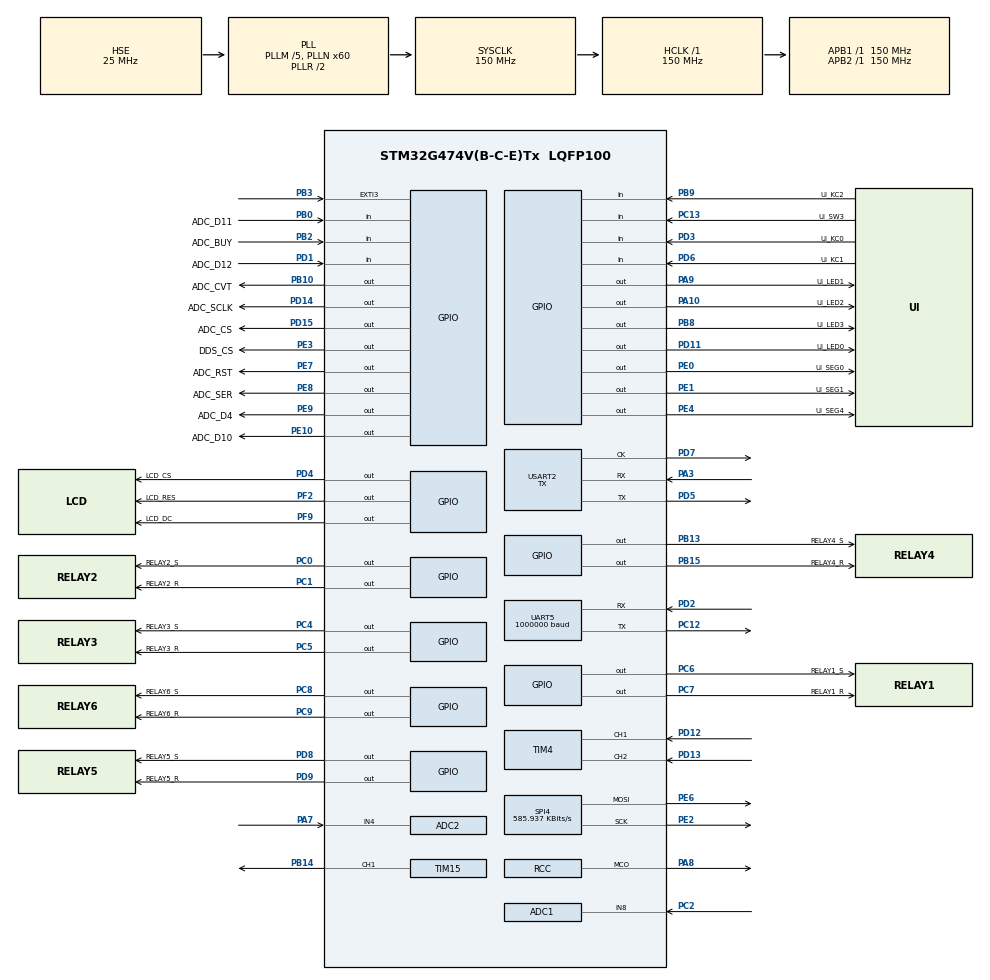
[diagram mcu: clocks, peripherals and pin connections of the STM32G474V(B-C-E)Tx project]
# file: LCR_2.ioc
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ADC1.Channel-3\#ChannelRegularConversion=ADC_CHANNEL_8
ADC1.ClockPrescaler=ADC_CLOCK_ASYNC_DIV1
ADC1.ExternalTrigConv=ADC_EXTERNALTRIG_T6_TRGO
ADC1.NbrOfConversionFlag=1
ADC1.OffsetNumber-3\#ChannelRegularConversion=ADC_OFFSET_NONE
ADC1.Rank-3\#ChannelRegularConversion=1
ADC1.SamplingTime-3\#ChannelRegularConversion=ADC_SAMPLETIME_2CYCLES_5
ADC1.master=1
ADC2.Channel-4\#ChannelRegularConversion=ADC_CHANNEL_4
ADC2.ClockPrescaler=ADC_CLOCK_ASYNC_DIV1
ADC2.ExternalTrigConv=ADC_EXTERNALTRIG_T6_TRGO
ADC2.NbrOfConversionFlag=1
ADC2.OffsetNumber-4\#ChannelRegularConversion=ADC_OFFSET_NONE
ADC2.Rank-4\#ChannelRegularConversion=1
ADC2.SamplingTime-4\#ChannelRegularConversion=ADC_SAMPLETIME_2CYCLES_5
CRC.CRCLength=CRC_POLYLENGTH_16B
CRC.DefaultInitValueUse=DEFAULT_INIT_VALUE_DISABLE
CRC.DefaultPolynomialUse=DEFAULT_POLYNOMIAL_DISABLE
CRC.GeneratingPolynomial=X12+X5+X0
CRC.InputDataInversionMode=CRC_INPUTDATA_INVERSION_NONE
Dma.ADC1.2.Direction=DMA_PERIPH_TO_MEMORY
Dma.ADC1.2.EventEnable=DISABLE
Dma.ADC1.2.Instance=DMA1_Channel1
Dma.ADC1.2.MemDataAlignment=DMA_MDATAALIGN_HALFWORD
Dma.ADC1.2.MemInc=DMA_MINC_ENABLE
Dma.ADC1.2.Mode=DMA_NORMAL
Dma.ADC1.2.PeriphDataAlignment=DMA_PDATAALIGN_HALFWORD
Dma.ADC1.2.PeriphInc=DMA_PINC_DISABLE
Dma.ADC1.2.Polarity=HAL_DMAMUX_REQ_GEN_RISING
Dma.ADC1.2.Priority=DMA_PRIORITY_LOW
Dma.ADC1.2.RequestNumber=1
Dma.ADC1.2.SignalID=NONE
Dma.ADC1.2.SyncEnable=DISABLE
Dma.ADC1.2.SyncPolarity=HAL_DMAMUX_SYNC_NO_EVENT
Dma.ADC1.2.SyncRequestNumber=1
Dma.ADC1.2.SyncSignalID=NONE
Dma.ADC2.3.Direction=DMA_PERIPH_TO_MEMORY
Dma.ADC2.3.EventEnable=DISABLE
Dma.ADC2.3.Instance=DMA1_Channel2
Dma.ADC2.3.MemDataAlignment=DMA_MDATAALIGN_HALFWORD
Dma.ADC2.3.MemInc=DMA_MINC_ENABLE
Dma.ADC2.3.Mode=DMA_NORMAL
Dma.ADC2.3.PeriphDataAlignment=DMA_PDATAALIGN_HALFWORD
Dma.ADC2.3.PeriphInc=DMA_PINC_DISABLE
Dma.ADC2.3.Polarity=HAL_DMAMUX_REQ_GEN_RISING
Dma.ADC2.3.Priority=DMA_PRIORITY_LOW
Dma.ADC2.3.RequestNumber=1
Dma.ADC2.3.SignalID=NONE
Dma.ADC2.3.SyncEnable=DISABLE
Dma.ADC2.3.SyncPolarity=HAL_DMAMUX_SYNC_NO_EVENT
Dma.ADC2.3.SyncRequestNumber=1
Dma.ADC2.3.SyncSignalID=NONE
Dma.CORDIC_READ.0.Direction=DMA_PERIPH_TO_MEMORY
Dma.CORDIC_READ.0.EventEnable=DISABLE
Dma.CORDIC_READ.0.Instance=DMA1_Channel3
Dma.CORDIC_READ.0.MemDataAlignment=DMA_MDATAALIGN_WORD
Dma.CORDIC_READ.0.MemInc=DMA_MINC_ENABLE
Dma.CORDIC_READ.0.Mode=DMA_NORMAL
Dma.CORDIC_READ.0.PeriphDataAlignment=DMA_PDATAALIGN_WORD
Dma.CORDIC_READ.0.PeriphInc=DMA_PINC_DISABLE
Dma.CORDIC_READ.0.Polarity=HAL_DMAMUX_REQ_GEN_RISING
Dma.CORDIC_READ.0.Priority=DMA_PRIORITY_LOW
Dma.CORDIC_READ.0.RequestNumber=1
Dma.CORDIC_READ.0.SignalID=NONE
Dma.CORDIC_READ.0.SyncEnable=DISABLE
Dma.CORDIC_READ.0.SyncPolarity=HAL_DMAMUX_SYNC_NO_EVENT
Dma.CORDIC_READ.0.SyncRequestNumber=1
Dma.CORDIC_READ.0.SyncSignalID=NONE
Dma.CORDIC_WRITE.1.Direction=DMA_MEMORY_TO_PERIPH
Dma.CORDIC_WRITE.1.EventEnable=DISABLE
Dma.CORDIC_WRITE.1.Instance=DMA1_Channel4
Dma.CORDIC_WRITE.1.MemDataAlignment=DMA_MDATAALIGN_WORD
Dma.CORDIC_WRITE.1.MemInc=DMA_MINC_ENABLE
Dma.CORDIC_WRITE.1.Mode=DMA_NORMAL
Dma.CORDIC_WRITE.1.PeriphDataAlignment=DMA_PDATAALIGN_WORD
Dma.CORDIC_WRITE.1.PeriphInc=DMA_PINC_DISABLE
Dma.CORDIC_WRITE.1.Polarity=HAL_DMAMUX_REQ_GEN_RISING
Dma.CORDIC_WRITE.1.Priority=DMA_PRIORITY_LOW
Dma.CORDIC_WRITE.1.RequestNumber=1
Dma.CORDIC_WRITE.1.SignalID=NONE
Dma.CORDIC_WRITE.1.SyncEnable=DISABLE
Dma.CORDIC_WRITE.1.SyncPolarity=HAL_DMAMUX_SYNC_NO_EVENT
Dma.CORDIC_WRITE.1.SyncRequestNumber=1
Dma.CORDIC_WRITE.1.SyncSignalID=NONE
Dma.Request0=CORDIC_READ
Dma.Request1=CORDIC_WRITE
Dma.Request2=ADC1
Dma.Request3=ADC2
Dma.Request4=UART5_RX
Dma.UART5_RX.4.Direction=DMA_PERIPH_TO_MEMORY
Dma.UART5_RX.4.EventEnable=DISABLE
Dma.UART5_RX.4.Instance=DMA1_Channel5
Dma.UART5_RX.4.MemDataAlignment=DMA_MDATAALIGN_BYTE
Dma.UART5_RX.4.MemInc=DMA_MINC_ENABLE
Dma.UART5_RX.4.Mode=DMA_CIRCULAR
Dma.UART5_RX.4.PeriphDataAlignment=DMA_PDATAALIGN_BYTE
Dma.UART5_RX.4.PeriphInc=DMA_PINC_DISABLE
Dma.UART5_RX.4.Polarity=HAL_DMAMUX_REQ_GEN_RISING
Dma.UART5_RX.4.Priority=DMA_PRIORITY_LOW
Dma.UART5_RX.4.RequestNumber=1
Dma.UART5_RX.4.SignalID=NONE
Dma.UART5_RX.4.SyncEnable=DISABLE
Dma.UART5_RX.4.SyncPolarity=HAL_DMAMUX_SYNC_NO_EVENT
Dma.UART5_RX.4.SyncRequestNumber=1
Dma.UART5_RX.4.SyncSignalID=NONE
Mcu.Family=STM32G4
Mcu.Name=STM32G474V(B-C-E)Tx
Mcu.Package=LQFP100
NVIC.DMA1_Channel1_IRQn=true\:0\:0\:false\:false\:true\:false\:true\:true
NVIC.DMA1_Channel2_IRQn=true\:0\:0\:false\:false\:true\:false\:true\:true
NVIC.DMA1_Channel3_IRQn=true\:0\:0\:false\:false\:true\:false\:true\:true
NVIC.DMA1_Channel4_IRQn=true\:0\:0\:false\:false\:true\:false\:true\:true
NVIC.DMA1_Channel5_IRQn=true\:0\:0\:false\:false\:true\:false\:true\:true
NVIC.PriorityGroup=NVIC_PRIORITYGROUP_4
NVIC.UART5_IRQn=true\:0\:0\:false\:false\:true\:true\:true\:true
PA10.GPIO_Label=UI_LED2
PA10.Signal=GPIO_Output
PA3.Mode=Synchronous
PA3.Signal=USART2_RX
PA7.Mode=IN4-Single-Ended
PA7.Signal=ADC2_IN4
PA8.GPIO_Speed=GPIO_SPEED_FREQ_VERY_HIGH
PA8.Mode=Clock-out
PA8.Signal=RCC_MCO
PA9.GPIO_Label=UI_LED1
PA9.Signal=GPIO_Output
PB0.GPIO_Label=ADC_D11
PB0.Signal=GPIO_Input
PB10.GPIO_Label=ADC_CVT
PB10.Signal=GPIO_Output
PB13.GPIO_Label=RELAY4_S
PB13.Signal=GPIO_Output
PB14.Signal=S_TIM15_CH1
PB15.GPIO_Label=RELAY4_R
PB15.Signal=GPIO_Output
PB2.GPIO_Label=ADC_BUY
PB2.Signal=GPIO_Input
PB3.Signal=GPXTI3
PB8-BOOT0.GPIO_Label=UI_LED3
PB8-BOOT0.Signal=GPIO_Output
PB9.GPIO_Label=UI_KC2
PB9.GPIO_PuPd=GPIO_PULLDOWN
PB9.Signal=GPIO_Input
PC0.GPIO_Label=RELAY2_S
PC0.Signal=GPIO_Output
PC1.GPIO_Label=RELAY2_R
PC1.Signal=GPIO_Output
PC12.Mode=Asynchronous
PC12.Signal=UART5_TX
PC13.GPIO_Label=UI_SW3
PC13.GPIO_PuPd=GPIO_PULLUP
PC13.Signal=GPIO_Input
PC2.Mode=IN8-Single-Ended
PC2.Signal=ADC1_IN8
PC4.GPIO_Label=RELAY3_S
PC4.Signal=GPIO_Output
PC5.GPIO_Label=RELAY3_R
PC5.Signal=GPIO_Output
PC6.GPIO_Label=RELAY1_S
PC6.Signal=GPIO_Output
PC7.GPIO_Label=RELAY1_R
PC7.Signal=GPIO_Output
PC8.GPIO_Label=RELAY6_S
PC8.Signal=GPIO_Output
PC9.GPIO_Label=RELAY6_R
PC9.Signal=GPIO_Output
PD1.GPIO_Label=ADC_D12
PD1.Signal=GPIO_Input
PD11.GPIO_Label=UI_LED0
PD11.Signal=GPIO_Output
PD12.Signal=S_TIM4_CH1
PD13.Signal=S_TIM4_CH2
PD14.GPIO_Label=ADC_SCLK
PD14.Signal=GPIO_Output
PD15.GPIO_Label=ADC_CS
PD15.Signal=GPIO_Output
PD2.Mode=Asynchronous
PD2.Signal=UART5_RX
PD3.GPIO_Label=UI_KC0
PD3.GPIO_PuPd=GPIO_PULLDOWN
PD3.Signal=GPIO_Input
PD4.GPIO_Label=LCD_CS
PD4.Signal=GPIO_Output
PD5.Mode=Synchronous
PD5.Signal=USART2_TX
PD6.GPIO_Label=UI_KC1
PD6.GPIO_PuPd=GPIO_PULLDOWN
PD6.Signal=GPIO_Input
PD7.Mode=Synchronous
PD7.Signal=USART2_CK
PD8.GPIO_Label=RELAY5_S
PD8.Signal=GPIO_Output
PD9.GPIO_Label=RELAY5_R
PD9.Signal=GPIO_Output
PE0.GPIO_Label=UI_SEG0
PE0.Signal=GPIO_Output
PE1.GPIO_Label=UI_SEG1
PE1.Signal=GPIO_Output
PE10.GPIO_Label=ADC_D10
PE10.GPIO_PuPd=GPIO_PULLUP
PE10.GPIO_Speed=GPIO_SPEED_FREQ_VERY_HIGH
PE10.PinState=GPIO_PIN_RESET
PE10.Signal=GPIO_Output
PE2.GPIO_PuPd=GPIO_PULLUP
PE2.GPIO_Speed=GPIO_SPEED_FREQ_VERY_HIGH
PE2.Mode=TX_Only_Simplex_Unidirect_Master
PE2.Signal=SPI4_SCK
PE3.GPIO_Label=DDS_CS
PE3.Signal=GPIO_Output
PE4.GPIO_Label=UI_SEG4
PE4.Signal=GPIO_Output
PE6.GPIO_Speed=GPIO_SPEED_FREQ_VERY_HIGH
PE6.Mode=TX_Only_Simplex_Unidirect_Master
PE6.Signal=SPI4_MOSI
PE7.GPIO_Label=ADC_RST
PE7.Signal=GPIO_Output
PE8.GPIO_Label=ADC_SER
PE8.Signal=GPIO_Output
PE9.GPIO_Label=ADC_D4
PE9.Signal=GPIO_Output
PF0-OSC_IN.Mode=HSE-External-Oscillator
PF0-OSC_IN.Signal=RCC_OSC_IN
PF1-OSC_OUT.Mode=HSE-External-Oscillator
PF1-OSC_OUT.Signal=RCC_OSC_OUT
PF2.GPIO_Label=LCD_RES
PF2.Signal=GPIO_Output
PF9.GPIO_Label=LCD_DC
PF9.Signal=GPIO_Output
ProjectManager.HeapSize=0x200
ProjectManager.StackSize=0x400
ProjectManager.TargetToolchain=STM32CubeIDE
RCC.ADC12CLockSelection=RCC_ADC12CLKSOURCE_PLL
RCC.ADC12Freq_Value=60000000
RCC.ADC345Freq_Value=150000000
RCC.AHBFreq_Value=150000000
RCC.APB1Freq_Value=150000000
RCC.APB1TimFreq_Value=150000000
RCC.APB2Freq_Value=150000000
RCC.APB2TimFreq_Value=150000000
RCC.CortexFreq_Value=150000000
RCC.EXTERNAL_CLOCK_VALUE=12288000
RCC.HCLKFreq_Value=150000000
RCC.HSE_VALUE=25000000
RCC.HSI48_VALUE=48000000
RCC.HSI_VALUE=16000000
RCC.LSE_VALUE=32768
RCC.PLLM=RCC_PLLM_DIV5
RCC.PLLN=60
RCC.PLLP=RCC_PLLP_DIV5
RCC.PLLSourceVirtual=RCC_PLLSOURCE_HSE
RCC.RCC_MCO1Source=RCC_MCO1SOURCE_HSE
RCC.SYSCLKFreq_VALUE=150000000
RCC.SYSCLKSource=RCC_SYSCLKSOURCE_PLLCLK
RCC.USBFreq_Value=150000000
RCC.VCOOutputFreq_Value=300000000
SH.S_TIM15_CH1.0=TIM15_CH1,PWM Generation1 CH1
SH.S_TIM4_CH1.0=TIM4_CH1,Encoder_Interface
SH.S_TIM4_CH2.0=TIM4_CH2,Encoder_Interface
SPI4.BaudRatePrescaler=SPI_BAUDRATEPRESCALER_256
SPI4.CLKPolarity=SPI_POLARITY_HIGH
SPI4.CalculateBaudRate=585.937 KBits/s
SPI4.DataSize=SPI_DATASIZE_16BIT
SPI4.Direction=SPI_DIRECTION_2LINES
SPI4.Mode=SPI_MODE_MASTER
SPI4.VirtualType=VM_MASTER
TIM15.Channel-PWM\ Generation1\ CH1=TIM_CHANNEL_1
TIM15.PeriodNoDither=14
TIM15.PulseNoDither_1=7
TIM6.PeriodNoDither=149
TIM6.TIM_MasterOutputTrigger=TIM_TRGO_UPDATE
UART5.BaudRate=1000000
USART2.Mode=MODE_TX
USART2.VirtualMode-Synchronous=VM_SYNC
VP_CORDIC_VS_CORDIC.Mode=CORDIC_Activate
VP_CRC_VS_CRC.Mode=CRC_Activate
VP_SYS_VS_DBSignals.Mode=DisableDeadBatterySignals
VP_TIM6_VS_ClockSourceINT.Mode=Enable_Timer
board=custom

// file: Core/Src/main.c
/* USER CODE BEGIN Header */
/**
  ******************************************************************************
  * @file           : main.c
  * @brief          : Main program body
  ******************************************************************************
  * @attention
  *
  * Copyright (c) 2025 STMicroelectronics.
  * All rights reserved.
  *
  * This software is licensed under terms that can be found in the LICENSE file
  * in the root directory of this software component.
  * If no LICENSE file comes with this software, it is provided AS-IS.
  *
  ******************************************************************************
  */
/* USER CODE END Header */
#include "main.h"
#include "adc.h"
#include "cordic.h"
#include "crc.h"
#include "dma.h"
#include "spi.h"
#include "tim.h"
#include "usart.h"
#include "gpio.h"

/* USER CODE BEGIN Includes */
#include "app.h"
/* USER CODE END Includes */

/* USER CODE BEGIN PD */
int __io_putchar(int ch)
{
  ITM_SendChar(ch);
  return ch;
}
/* USER CODE END PD */

void SystemClock_Config(void);

int main(void)
{

  /* MCU Configuration--------------------------------------------------------*/

  /* Reset of all peripherals, Initializes the Flash interface and the Systick. */
  HAL_Init();

  /* Configure the system clock */
  SystemClock_Config();

  /* Initialize all configured peripherals */
  MX_GPIO_Init();
  MX_DMA_Init();
  MX_CORDIC_Init();
  MX_TIM6_Init();
  MX_ADC1_Init();
  MX_ADC2_Init();
  MX_UART5_Init();
  MX_CRC_Init();
  MX_USART2_Init();
  MX_SPI4_Init();
  MX_TIM4_Init();
  MX_TIM15_Init();
  /* USER CODE BEGIN 2 */
  HAL_TIM_Base_Start(&htim6);
  HAL_TIM_Base_Start(&htim15);
  HAL_TIM_PWM_Start(&htim15, TIM_CHANNEL_1);
  setup();

  /* USER CODE END 2 */

  /* Infinite loop */
  while (1)
  {

    /* USER CODE BEGIN 3 */

	  loop();
  }
  /* USER CODE END 3 */
}

void SystemClock_Config(void)
{
  RCC_OscInitTypeDef RCC_OscInitStruct = {0};
  RCC_ClkInitTypeDef RCC_ClkInitStruct = {0};

  /** Configure the main internal regulator output voltage
  */
  HAL_PWREx_ControlVoltageScaling(PWR_REGULATOR_VOLTAGE_SCALE1);

  /** Initializes the RCC Oscillators according to the specified parameters
  * in the RCC_OscInitTypeDef structure.
  */
  RCC_OscInitStruct.OscillatorType = RCC_OSCILLATORTYPE_HSE;
  RCC_OscInitStruct.HSEState = RCC_HSE_ON;
  RCC_OscInitStruct.PLL.PLLState = RCC_PLL_ON;
  RCC_OscInitStruct.PLL.PLLSource = RCC_PLLSOURCE_HSE;
  RCC_OscInitStruct.PLL.PLLM = RCC_PLLM_DIV5;
  RCC_OscInitStruct.PLL.PLLN = 60;
  RCC_OscInitStruct.PLL.PLLP = RCC_PLLP_DIV5;
  RCC_OscInitStruct.PLL.PLLQ = RCC_PLLQ_DIV2;
  RCC_OscInitStruct.PLL.PLLR = RCC_PLLR_DIV2;
  if (HAL_RCC_OscConfig(&RCC_OscInitStruct) != HAL_OK)
  {
    Error_Handler();
  }

  /** Initializes the CPU, AHB and APB buses clocks
  */
  RCC_ClkInitStruct.ClockType = RCC_CLOCKTYPE_HCLK|RCC_CLOCKTYPE_SYSCLK
                              |RCC_CLOCKTYPE_PCLK1|RCC_CLOCKTYPE_PCLK2;
  RCC_ClkInitStruct.SYSCLKSource = RCC_SYSCLKSOURCE_PLLCLK;
  RCC_ClkInitStruct.AHBCLKDivider = RCC_SYSCLK_DIV1;
  RCC_ClkInitStruct.APB1CLKDivider = RCC_HCLK_DIV1;
  RCC_ClkInitStruct.APB2CLKDivider = RCC_HCLK_DIV1;

  if (HAL_RCC_ClockConfig(&RCC_ClkInitStruct, FLASH_LATENCY_4) != HAL_OK)
  {
    Error_Handler();
  }
  HAL_RCC_MCOConfig(RCC_MCO1, RCC_MCO1SOURCE_HSE, RCC_MCODIV_1);
}

void Error_Handler(void)
{
  __disable_irq();
  while (1)
  {
  }
}
